# A31L22x register map
Vendor: VENDOR ABOV Semiconductor Co., Ltd.; Series: A31L22x; File version: 1.0
CPU: CM0+ r0p1, little endian, no MPU, no FPU, VTOR, 2 interrupt priority bits
Registers are 32-bit, read-write, reset 0x0 unless marked. A register's access mark holds for its fields unless they carry their own. Offsets are from the block's base; [hi:lo] are bit positions.

## FMC — Flash Memory Controller
Base 0x40001B00
0x00 ADR reset 0x5FFFFF80 — Flash Memory Address Register
  [31:0] ADDR — Flash Memory Address Pointer
0x04 IDR1 — Flash Memory Identification Register 1
  [31:0] ID1 — Flash Memory Identification 1
    0x8192A3B=Value (ID1 Value (0x08192a3b))
0x08 IDR2 — Flash Memory Identification Register 2
  [31:0] ID2 — Flash Memory Identification 2
    0x4C5D6E7F=Value (ID2 Value (0x4c5d6e7f))
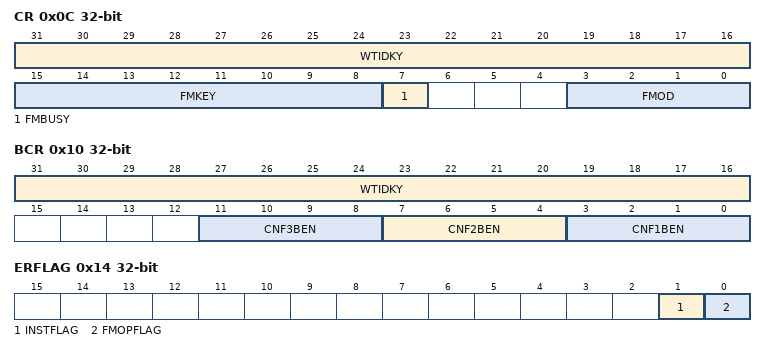
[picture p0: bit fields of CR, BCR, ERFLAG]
0x0C CR — Flash Memory Control Register
  [31:16] WTIDKY wo — Write Identification Key (0x6c93)
    0x6C93=Value (Key Value (0x6c93))
  [15:8] FMKEY — Flash Memory Operation Area Selection
    0=NoSelect (Not select any area but for flash page buffer reset mode); 56=ConfigurationOptionArea (Select 'configure option area' for flash memory erase/write); 164=Flash (Select 'flash memory area' for flash memory erase/write)
  [7] FMBUSY ro — Flash Memory Operation Mode Busy
    0=NoEffect; 1=Busy
  [3:0] FMOD — Flash Memory Operation Mode Selection
    1=PageBufferReset ('Flash page buffer reset mode' and start regardless of the flash operation rule); 2=PageErase ('Flash page erase mode' and start when the flash operation rule is satisfied.); 4=PageWrite ('Flash page write mode' and start when the flash operation rule is satisfied.); 8=BulkErase ('Flash bulk erase mode' and start when the flash operation rule is satisfied.)
0x10 BCR — Flash Memory Configure Area Bulk Erase Control Register
  [31:16] WTIDKY wo — Write Identification Key (0xc1be)
    0xC1BE=Value (Key Value (0xc1be))
  [11:8] CNF3BEN — Configure Option Page 3 Bulk Erase Enable
    5=Enable (Permit 'configure option page 3' erase when bulk erase)
  [7:4] CNF2BEN — Configure Option Page 2 Bulk Erase Enable
    5=Enable (Permit 'configure option page 2' erase when bulk erase)
  [3:0] CNF1BEN — Configure Option Page 1 Bulk Erase Enable
    5=Enable (Permit 'configure option page 1' erase when bulk erase)
0x14 ERFLAG — Flash Memory Error Flag
  [1] INSTFLAG — Don't care
  [0] FMOPFLAG — Error bit of Flash Memory Operation Procedure
    0=NoWrongProcedure; 1=WrongProcedure (A wrong procedure occurred, This bit is cleared to '0' when write '1'.)
0x100 PAGEBUF wo — Flash Memory Page Buffer Area (128bytes/Accessed by 32bit Word Only)

## CRC — Cyclic Redundancy Check and Checksum
Base 0x30001000
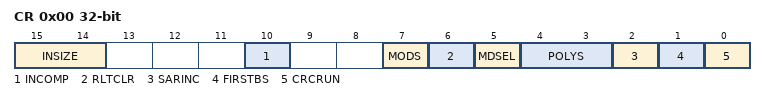
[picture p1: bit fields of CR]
0x00 CR — CRC/Checksum Control Register
  [15:14] INSIZE — Input Data Size Selection
    0=32-bit is the input data size; 1=16-bit is the input data size; 2=8-bit is the input data size
  [10] INCOMP — Input Data Complement
    0=Disable (No effect.); 1=Enable (1's complement of input data)
  [7] MODS — User/Auto Mode Selection
    0=User Mode (Calculate every data written to the CRC_IN register); 1=Auto Mode (Calculate till CRC_SADR == CRC_EADR)
  [6] RLTCLR — CRC/Checksum Result Data Register (CRC_RLT) Initialization
    0=NoEffect; 1=Initialize the CRC_RLT register with the value of CRC_INIT. (This bit is automatically cleared to '0' after operation.)
  [5] MDSEL — CRC/Checksum Selection
    0=CRC (Select CRC.); 1=Checksum (Select Checksum.)
  [4:3] POLYS — Polynomial Selection (CRC only)
    0=CRC16_CCITT (CRC16-CCITT (G1(x) = x16 + x12 + x5 + 1)); 1=CRC16 (CRC16 (G2(x) = x16 + x15 + x2 + 1)); 2=CRC8 (CRC8 (G3(x) = x8 + x2 + x + 1)); 3=CRC32 (CRC32 (G4(x) = x32 + x26 + x23 + x22 + x16 + x12 + x11 + x10 +x8 + x7 + x5 + x4 + x2 + x + 1))
  [2] SARINC — CRC/Checksum Start Address Auto Increment Control (User mode only)
    0=Disable (No effect.); 1=Enable (The CRC/Checksum start address register is incremented as the selected input size every writing to the CRC_IN register.)
  [1] FIRSTBS — First Shifted-in Selection (CRC only)
    0=msbFirst; 1=lsbFirst
  [0] CRCRUN — CRC/Checksum Start/Stop Control
    0=Stop (Not busy. The CRC operation can be finished by writing '0' to this bit while running.); 1=Start CRC operation. This bit is automatically cleared to '0' when the value of CRC_SADR register reaches the value of CRC_EADR register.
0x04 IN — CRC/Checksum Input Data Register
  [31:0] INDATA — CRC Input Data
0x08 RLT ro reset 0xFFFFFFFF — CRC/Checksum Result Data Register
  [31:0] RLTDATA — CRC Result Data
0x0C INIT — CRC/Checksum Initial Data Register
  [31:0] INIDATA — CRC Initial Data
0x10 SADR reset 0x10000000 — CRC/Checksum Start Address Register
  [31:0] SADR — CRC Start Address
0x14 EADR reset 0x10007FFC — CRC/Checksum End Address Register
  [31:0] EADR — CRC End Address
